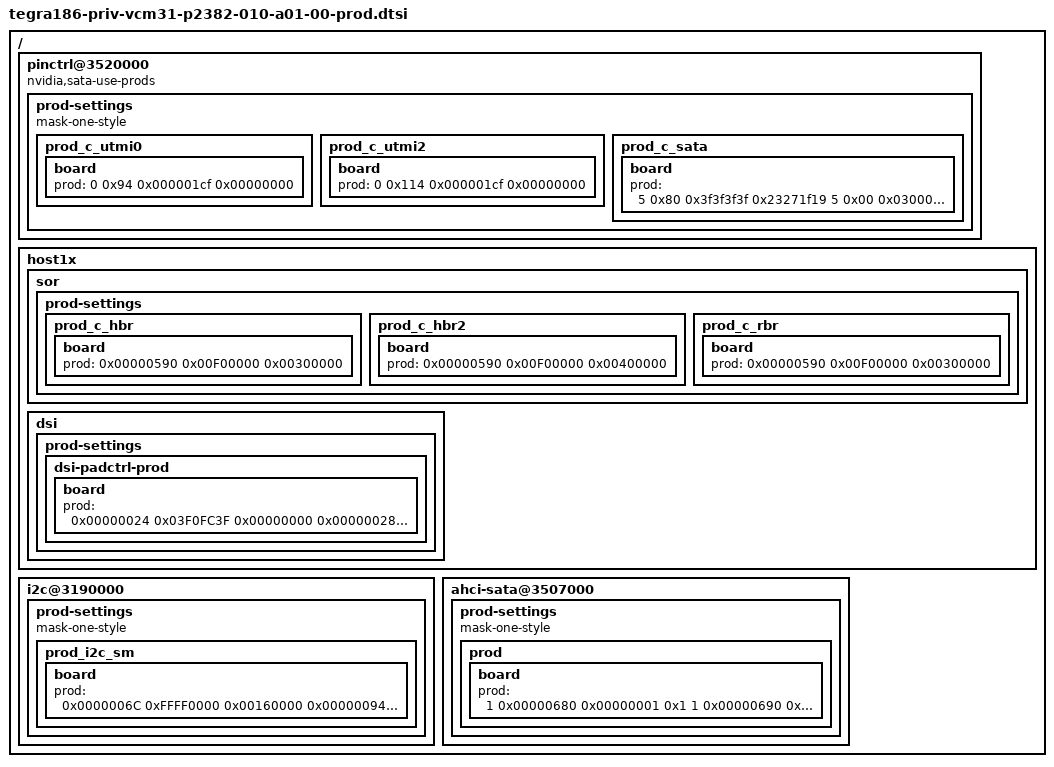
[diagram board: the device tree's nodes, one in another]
/*
 * P2382(Sunstreaker) specific Prod configuration.
 *
 * Copyright (c) 2016, NVIDIA CORPORATION.  All rights reserved.
 *
 * This program is free software; you can redistribute it and/or modify
 * it under the terms of the GNU General Public License as published by
 * the Free Software Foundation; version 2 of the License.
 *
 */

#include "tegra186-soc/tegra186-soc-vcm-prod.dtsi"

/ {

	pinctrl@3520000 {
		nvidia,sata-use-prods;
		prod-settings {
			#prod-cells = <4>;
			mask-one-style;
			prod_c_utmi0 {
				board {
					prod = <0 0x94 0x000001cf 0x00000000>;
				};
			};
			prod_c_utmi2 {
				board {
					prod = <0 0x114 0x000001cf 0x00000000>;
				};
			};
			prod_c_sata {
				board {
					prod = <5 0x80 0x3f3f3f3f 0x23271f19
						5 0x00 0x03000000 0x0
						5 0x8c 0x003f003f 0x000a0007>;
				};
			};
		};
	};

	host1x {
		sor{
			prod-settings {
				prod_c_hbr {
					board {
						prod = <
							0x00000590 0x00F00000 0x00300000
						>;
					};
				};
				prod_c_hbr2 {
					board {
						prod = <
							0x00000590 0x00F00000 0x00400000
						>;
					};

				};
				prod_c_rbr {
					board {
						prod = <
							0x00000590 0x00F00000 0x00300000
						>;
					};
				};
			};
		};

		dsi {
			prod-settings {
				dsi-padctrl-prod {
					board {
						prod = <
							0x00000024 0x03F0FC3F 0x00000000
							0x00000028 0x00333333 0x00000000
							0x00000030 0x00FFFFFF 0x00000000
							0x00000034 0x00FFFFFF 0x00777777
							0x00000054 0x03F0FC3F 0x00000000
							0x00000058 0x00333333 0x00000000
							0x00000060 0x00FFFFFF 0x00000000
							0x00000064 0x00FFFFFF 0x00777777
							0x00000084 0x03F0FC3F 0x00000000
							0x00000088 0x00333333 0x00000000
							0x00000090 0x00FFFFFF 0x00000000
							0x00000094 0x00FFFFFF 0x00777777
							0x000000B4 0x03F0FC3F 0x00000000
							0x000000B8 0x00333333 0x00000000
							0x000000C0 0x00FFFFFF 0x00000000
							0x000000C4 0x00FFFFFF 0x00777777
						>;
					};
				};
			};
		};
	};

	i2c@3190000 {  //i2c3, dp_aux_ch1_i2c
		prod-settings {
			mask-one-style;
			prod_i2c_sm {
				board {
					prod = <0x0000006C 0xFFFF0000 0x00160000
						0x00000094 0x00003F3F 0x00000304>;
				};
			};
		};
	};

	ahci-sata@3507000 {
		prod-settings {
			mask-one-style;
			prod {
				board {
					prod = <
						1 0x00000680 0x00000001 0x1
						1 0x00000690 0x3FFFFFFF 0x00000715	// T_SATA0_CHX_PHY_CTRL1_GEN1	31:0
						1 0x00000694 0x3FFFFFFF 0x0000A018	// T_SATA0_CHX_PHY_CTRL1_GEN2	31:0
						1 0x00000680 0x00000001 0x0
					>;
				};
			};
		};
	};
};
